# VPAC0_VISS_ECC_AGGR register map
Vendor: Texas Instruments
Peripheral module from a debugger description file (folder J721S2).
Registers are 32-bit, access not given, reset 0x0 unless marked. A register's access mark holds for its fields unless they carry their own. Offsets are as the file gives them; lines under a group give offsets from that group; [hi:lo] are bit positions; {n}, {i} and the like mark numbered series; 'fields as' and 'values as' point back to an identical list; <NAME> marks a mode.

## VPAC0_VISS_ECC_AGGR
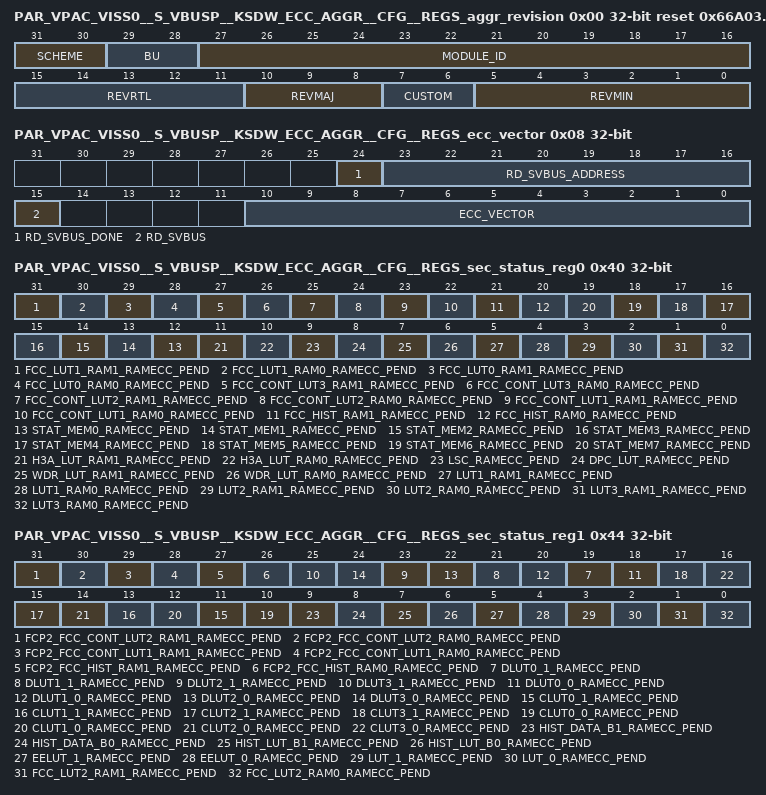
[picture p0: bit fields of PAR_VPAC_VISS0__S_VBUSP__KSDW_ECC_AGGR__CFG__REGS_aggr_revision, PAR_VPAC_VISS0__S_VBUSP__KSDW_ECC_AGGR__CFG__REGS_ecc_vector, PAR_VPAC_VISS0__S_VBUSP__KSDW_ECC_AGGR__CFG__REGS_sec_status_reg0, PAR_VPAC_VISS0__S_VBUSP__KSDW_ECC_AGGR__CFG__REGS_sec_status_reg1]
0x00 PAR_VPAC_VISS0__S_VBUSP__KSDW_ECC_AGGR__CFG__REGS_aggr_revision ro reset 0x66A03A01 — Revision parameters
  [31:30] SCHEME
  [29:28] BU
  [27:16] MODULE_ID
  [15:11] REVRTL — RTL version
  [10:8] REVMAJ — Major version
  [7:6] CUSTOM — Custom version
  [5:0] REVMIN — Minor version
0x08 PAR_VPAC_VISS0__S_VBUSP__KSDW_ECC_AGGR__CFG__REGS_ecc_vector — ECC Vector Register
  [24] RD_SVBUS_DONE — Status to indicate if read on serial VBUS is complete, write of any value will clear this bit. (access R/W1TC)
  [23:16] RD_SVBUS_ADDRESS rw — Read address
  [15] RD_SVBUS — Write 1 to trigger a read on the serial VBUS (access R/W1TS)
  [10:0] ECC_VECTOR rw — Value written to select the corresponding ECC RAM for control or status
0x0C PAR_VPAC_VISS0__S_VBUSP__KSDW_ECC_AGGR__CFG__REGS_misc_status ro reset 0x5D — Misc Status
  [10:0] NUM_RAMS — Indicates the number of RAMS serviced by the ECC aggregator
0x10 PAR_VPAC_VISS0__S_VBUSP__KSDW_ECC_AGGR__CFG__REGS_reserved_svbus rw — Reference other documents that contain the ECC RAM wrapper and EDC controller serial vbus register sets.
  [31:0] DATA — Serial VBUS register data
0x3C PAR_VPAC_VISS0__S_VBUSP__KSDW_ECC_AGGR__CFG__REGS_sec_eoi_reg — EOI Register
  [0] EOI_WR — EOI Register (access R/W1TS)
0x40 PAR_VPAC_VISS0__S_VBUSP__KSDW_ECC_AGGR__CFG__REGS_sec_status_reg0 — Interrupt Status Register 0
  [31] FCC_LUT1_RAM1_RAMECC_PEND — Interrupt Pending Status for fcc_lut1_ram1_ramecc_pend (access R/W1TS)
  [30] FCC_LUT1_RAM0_RAMECC_PEND — Interrupt Pending Status for fcc_lut1_ram0_ramecc_pend (access R/W1TS)
  [29] FCC_LUT0_RAM1_RAMECC_PEND — Interrupt Pending Status for fcc_lut0_ram1_ramecc_pend (access R/W1TS)
  [28] FCC_LUT0_RAM0_RAMECC_PEND — Interrupt Pending Status for fcc_lut0_ram0_ramecc_pend (access R/W1TS)
  [27] FCC_CONT_LUT3_RAM1_RAMECC_PEND — Interrupt Pending Status for fcc_cont_lut3_ram1_ramecc_pend (access R/W1TS)
  [26] FCC_CONT_LUT3_RAM0_RAMECC_PEND — Interrupt Pending Status for fcc_cont_lut3_ram0_ramecc_pend (access R/W1TS)
  [25] FCC_CONT_LUT2_RAM1_RAMECC_PEND — Interrupt Pending Status for fcc_cont_lut2_ram1_ramecc_pend (access R/W1TS)
  [24] FCC_CONT_LUT2_RAM0_RAMECC_PEND — Interrupt Pending Status for fcc_cont_lut2_ram0_ramecc_pend (access R/W1TS)
  [23] FCC_CONT_LUT1_RAM1_RAMECC_PEND — Interrupt Pending Status for fcc_cont_lut1_ram1_ramecc_pend (access R/W1TS)
  [22] FCC_CONT_LUT1_RAM0_RAMECC_PEND — Interrupt Pending Status for fcc_cont_lut1_ram0_ramecc_pend (access R/W1TS)
  [21] FCC_HIST_RAM1_RAMECC_PEND — Interrupt Pending Status for fcc_hist_ram1_ramecc_pend (access R/W1TS)
  [20] FCC_HIST_RAM0_RAMECC_PEND — Interrupt Pending Status for fcc_hist_ram0_ramecc_pend (access R/W1TS)
  [n+12] STAT_MEM{n}_RAMECC_PEND (n=0..7) — Interrupt Pending Status for stat_mem{n}_ramecc_pend (access R/W1TS)
  [11] H3A_LUT_RAM1_RAMECC_PEND — Interrupt Pending Status for h3a_lut_ram1_ramecc_pend (access R/W1TS)
  [10] H3A_LUT_RAM0_RAMECC_PEND — Interrupt Pending Status for h3a_lut_ram0_ramecc_pend (access R/W1TS)
  [9] LSC_RAMECC_PEND — Interrupt Pending Status for lsc_ramecc_pend (access R/W1TS)
  [8] DPC_LUT_RAMECC_PEND — Interrupt Pending Status for dpc_lut_ramecc_pend (access R/W1TS)
  [7] WDR_LUT_RAM1_RAMECC_PEND — Interrupt Pending Status for wdr_lut_ram1_ramecc_pend (access R/W1TS)
  [6] WDR_LUT_RAM0_RAMECC_PEND — Interrupt Pending Status for wdr_lut_ram0_ramecc_pend (access R/W1TS)
  [5] LUT1_RAM1_RAMECC_PEND — Interrupt Pending Status for lut1_ram1_ramecc_pend (access R/W1TS)
  [4] LUT1_RAM0_RAMECC_PEND — Interrupt Pending Status for lut1_ram0_ramecc_pend (access R/W1TS)
  [3] LUT2_RAM1_RAMECC_PEND — Interrupt Pending Status for lut2_ram1_ramecc_pend (access R/W1TS)
  [2] LUT2_RAM0_RAMECC_PEND — Interrupt Pending Status for lut2_ram0_ramecc_pend (access R/W1TS)
  [1] LUT3_RAM1_RAMECC_PEND — Interrupt Pending Status for lut3_ram1_ramecc_pend (access R/W1TS)
  [0] LUT3_RAM0_RAMECC_PEND — Interrupt Pending Status for lut3_ram0_ramecc_pend (access R/W1TS)
0x44 PAR_VPAC_VISS0__S_VBUSP__KSDW_ECC_AGGR__CFG__REGS_sec_status_reg1 — Interrupt Status Register 1
  [31] FCP2_FCC_CONT_LUT2_RAM1_RAMECC_PEND — Interrupt Pending Status for fcp2_fcc_cont_lut2_ram1_ramecc_pend (access R/W1TS)
  [30] FCP2_FCC_CONT_LUT2_RAM0_RAMECC_PEND — Interrupt Pending Status for fcp2_fcc_cont_lut2_ram0_ramecc_pend (access R/W1TS)
  [29] FCP2_FCC_CONT_LUT1_RAM1_RAMECC_PEND — Interrupt Pending Status for fcp2_fcc_cont_lut1_ram1_ramecc_pend (access R/W1TS)
  [28] FCP2_FCC_CONT_LUT1_RAM0_RAMECC_PEND — Interrupt Pending Status for fcp2_fcc_cont_lut1_ram0_ramecc_pend (access R/W1TS)
  [27] FCP2_FCC_HIST_RAM1_RAMECC_PEND — Interrupt Pending Status for fcp2_fcc_hist_ram1_ramecc_pend (access R/W1TS)
  [26] FCP2_FCC_HIST_RAM0_RAMECC_PEND — Interrupt Pending Status for fcp2_fcc_hist_ram0_ramecc_pend (access R/W1TS)
  [2n+19] DLUT{n}_1_RAMECC_PEND (n=0..3) — Interrupt Pending Status for dlut{n}_1_ramecc_pend (access R/W1TS)
  [2n+18] DLUT{n}_0_RAMECC_PEND (n=0..3) — Interrupt Pending Status for dlut{n}_0_ramecc_pend (access R/W1TS)
  [2n+11] CLUT{n}_1_RAMECC_PEND (n=0..3) — Interrupt Pending Status for clut{n}_1_ramecc_pend (access R/W1TS)
  [2n+10] CLUT{n}_0_RAMECC_PEND (n=0..3) — Interrupt Pending Status for clut{n}_0_ramecc_pend (access R/W1TS)
  [9] HIST_DATA_B1_RAMECC_PEND — Interrupt Pending Status for hist_data_b1_ramecc_pend (access R/W1TS)
  [8] HIST_DATA_B0_RAMECC_PEND — Interrupt Pending Status for hist_data_b0_ramecc_pend (access R/W1TS)
  [7] HIST_LUT_B1_RAMECC_PEND — Interrupt Pending Status for hist_lut_b1_ramecc_pend (access R/W1TS)
  [6] HIST_LUT_B0_RAMECC_PEND — Interrupt Pending Status for hist_lut_b0_ramecc_pend (access R/W1TS)
  [5] EELUT_1_RAMECC_PEND — Interrupt Pending Status for eelut_1_ramecc_pend (access R/W1TS)
  [4] EELUT_0_RAMECC_PEND — Interrupt Pending Status for eelut_0_ramecc_pend (access R/W1TS)
  [3] LUT_1_RAMECC_PEND — Interrupt Pending Status for lut_1_ramecc_pend (access R/W1TS)
  [2] LUT_0_RAMECC_PEND — Interrupt Pending Status for lut_0_ramecc_pend (access R/W1TS)
  [1] FCC_LUT2_RAM1_RAMECC_PEND — Interrupt Pending Status for fcc_lut2_ram1_ramecc_pend (access R/W1TS)
  [0] FCC_LUT2_RAM0_RAMECC_PEND — Interrupt Pending Status for fcc_lut2_ram0_ramecc_pend (access R/W1TS)
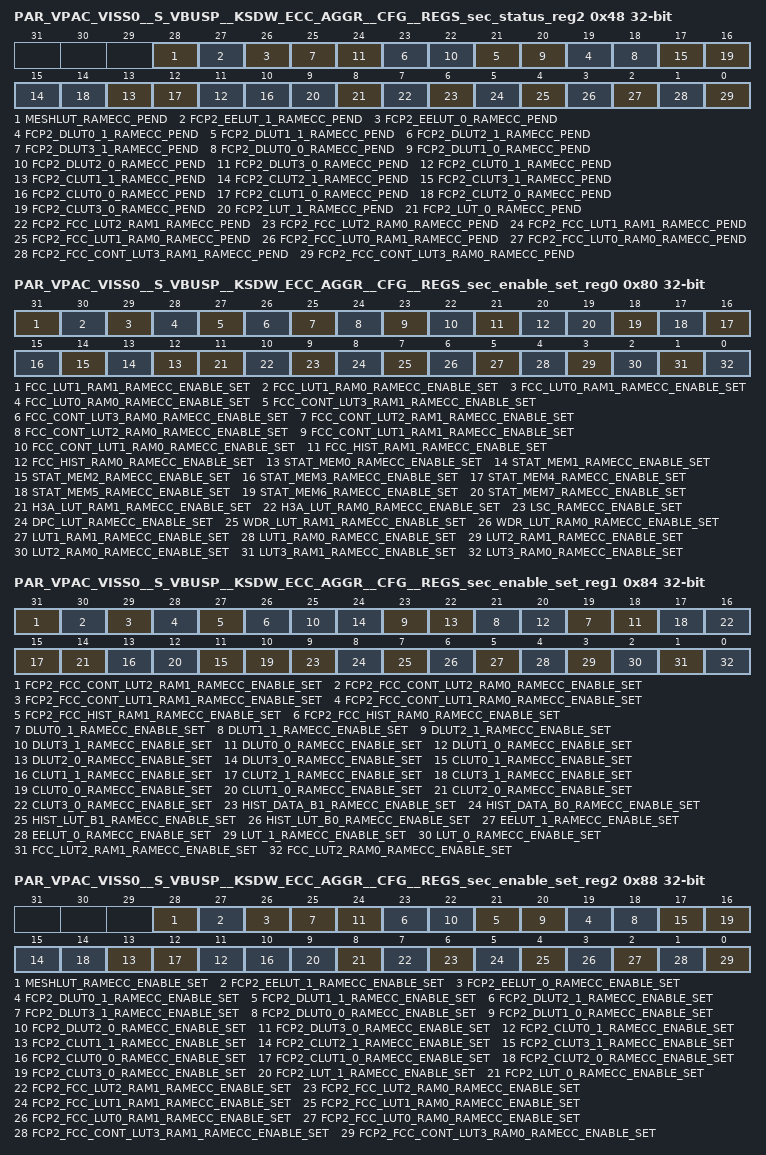
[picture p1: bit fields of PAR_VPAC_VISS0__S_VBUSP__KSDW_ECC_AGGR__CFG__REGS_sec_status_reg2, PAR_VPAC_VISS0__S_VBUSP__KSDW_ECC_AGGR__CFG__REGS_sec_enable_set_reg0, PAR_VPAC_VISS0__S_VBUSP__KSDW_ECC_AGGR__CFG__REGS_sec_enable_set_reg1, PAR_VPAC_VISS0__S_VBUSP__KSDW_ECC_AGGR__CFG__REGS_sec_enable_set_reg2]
0x48 PAR_VPAC_VISS0__S_VBUSP__KSDW_ECC_AGGR__CFG__REGS_sec_status_reg2 — Interrupt Status Register 2
  [28] MESHLUT_RAMECC_PEND — Interrupt Pending Status for meshlut_ramecc_pend (access R/W1TS)
  [27] FCP2_EELUT_1_RAMECC_PEND — Interrupt Pending Status for fcp2_eelut_1_ramecc_pend (access R/W1TS)
  [26] FCP2_EELUT_0_RAMECC_PEND — Interrupt Pending Status for fcp2_eelut_0_ramecc_pend (access R/W1TS)
  [2n+19] FCP2_DLUT{n}_1_RAMECC_PEND (n=0..3) — Interrupt Pending Status for fcp2_dlut{n}_1_ramecc_pend (access R/W1TS)
  [2n+18] FCP2_DLUT{n}_0_RAMECC_PEND (n=0..3) — Interrupt Pending Status for fcp2_dlut{n}_0_ramecc_pend (access R/W1TS)
  [2n+11] FCP2_CLUT{n}_1_RAMECC_PEND (n=0..3) — Interrupt Pending Status for fcp2_clut{n}_1_ramecc_pend (access R/W1TS)
  [2n+10] FCP2_CLUT{n}_0_RAMECC_PEND (n=0..3) — Interrupt Pending Status for fcp2_clut{n}_0_ramecc_pend (access R/W1TS)
  [9] FCP2_LUT_1_RAMECC_PEND — Interrupt Pending Status for fcp2_lut_1_ramecc_pend (access R/W1TS)
  [8] FCP2_LUT_0_RAMECC_PEND — Interrupt Pending Status for fcp2_lut_0_ramecc_pend (access R/W1TS)
  [7] FCP2_FCC_LUT2_RAM1_RAMECC_PEND — Interrupt Pending Status for fcp2_fcc_lut2_ram1_ramecc_pend (access R/W1TS)
  [6] FCP2_FCC_LUT2_RAM0_RAMECC_PEND — Interrupt Pending Status for fcp2_fcc_lut2_ram0_ramecc_pend (access R/W1TS)
  [5] FCP2_FCC_LUT1_RAM1_RAMECC_PEND — Interrupt Pending Status for fcp2_fcc_lut1_ram1_ramecc_pend (access R/W1TS)
  [4] FCP2_FCC_LUT1_RAM0_RAMECC_PEND — Interrupt Pending Status for fcp2_fcc_lut1_ram0_ramecc_pend (access R/W1TS)
  [3] FCP2_FCC_LUT0_RAM1_RAMECC_PEND — Interrupt Pending Status for fcp2_fcc_lut0_ram1_ramecc_pend (access R/W1TS)
  [2] FCP2_FCC_LUT0_RAM0_RAMECC_PEND — Interrupt Pending Status for fcp2_fcc_lut0_ram0_ramecc_pend (access R/W1TS)
  [1] FCP2_FCC_CONT_LUT3_RAM1_RAMECC_PEND — Interrupt Pending Status for fcp2_fcc_cont_lut3_ram1_ramecc_pend (access R/W1TS)
  [0] FCP2_FCC_CONT_LUT3_RAM0_RAMECC_PEND — Interrupt Pending Status for fcp2_fcc_cont_lut3_ram0_ramecc_pend (access R/W1TS)
0x80 PAR_VPAC_VISS0__S_VBUSP__KSDW_ECC_AGGR__CFG__REGS_sec_enable_set_reg0 — Interrupt Enable Set Register 0
  [31] FCC_LUT1_RAM1_RAMECC_ENABLE_SET — Interrupt Enable Set Register for fcc_lut1_ram1_ramecc_pend (access R/W1TS)
  [30] FCC_LUT1_RAM0_RAMECC_ENABLE_SET — Interrupt Enable Set Register for fcc_lut1_ram0_ramecc_pend (access R/W1TS)
  [29] FCC_LUT0_RAM1_RAMECC_ENABLE_SET — Interrupt Enable Set Register for fcc_lut0_ram1_ramecc_pend (access R/W1TS)
  [28] FCC_LUT0_RAM0_RAMECC_ENABLE_SET — Interrupt Enable Set Register for fcc_lut0_ram0_ramecc_pend (access R/W1TS)
  [27] FCC_CONT_LUT3_RAM1_RAMECC_ENABLE_SET — Interrupt Enable Set Register for fcc_cont_lut3_ram1_ramecc_pend (access R/W1TS)
  [26] FCC_CONT_LUT3_RAM0_RAMECC_ENABLE_SET — Interrupt Enable Set Register for fcc_cont_lut3_ram0_ramecc_pend (access R/W1TS)
  [25] FCC_CONT_LUT2_RAM1_RAMECC_ENABLE_SET — Interrupt Enable Set Register for fcc_cont_lut2_ram1_ramecc_pend (access R/W1TS)
  [24] FCC_CONT_LUT2_RAM0_RAMECC_ENABLE_SET — Interrupt Enable Set Register for fcc_cont_lut2_ram0_ramecc_pend (access R/W1TS)
  [23] FCC_CONT_LUT1_RAM1_RAMECC_ENABLE_SET — Interrupt Enable Set Register for fcc_cont_lut1_ram1_ramecc_pend (access R/W1TS)
  [22] FCC_CONT_LUT1_RAM0_RAMECC_ENABLE_SET — Interrupt Enable Set Register for fcc_cont_lut1_ram0_ramecc_pend (access R/W1TS)
  [21] FCC_HIST_RAM1_RAMECC_ENABLE_SET — Interrupt Enable Set Register for fcc_hist_ram1_ramecc_pend (access R/W1TS)
  [20] FCC_HIST_RAM0_RAMECC_ENABLE_SET — Interrupt Enable Set Register for fcc_hist_ram0_ramecc_pend (access R/W1TS)
  [n+12] STAT_MEM{n}_RAMECC_ENABLE_SET (n=0..7) — Interrupt Enable Set Register for stat_mem{n}_ramecc_pend (access R/W1TS)
  [11] H3A_LUT_RAM1_RAMECC_ENABLE_SET — Interrupt Enable Set Register for h3a_lut_ram1_ramecc_pend (access R/W1TS)
  [10] H3A_LUT_RAM0_RAMECC_ENABLE_SET — Interrupt Enable Set Register for h3a_lut_ram0_ramecc_pend (access R/W1TS)
  [9] LSC_RAMECC_ENABLE_SET — Interrupt Enable Set Register for lsc_ramecc_pend (access R/W1TS)
  [8] DPC_LUT_RAMECC_ENABLE_SET — Interrupt Enable Set Register for dpc_lut_ramecc_pend (access R/W1TS)
  [7] WDR_LUT_RAM1_RAMECC_ENABLE_SET — Interrupt Enable Set Register for wdr_lut_ram1_ramecc_pend (access R/W1TS)
  [6] WDR_LUT_RAM0_RAMECC_ENABLE_SET — Interrupt Enable Set Register for wdr_lut_ram0_ramecc_pend (access R/W1TS)
  [5] LUT1_RAM1_RAMECC_ENABLE_SET — Interrupt Enable Set Register for lut1_ram1_ramecc_pend (access R/W1TS)
  [4] LUT1_RAM0_RAMECC_ENABLE_SET — Interrupt Enable Set Register for lut1_ram0_ramecc_pend (access R/W1TS)
  [3] LUT2_RAM1_RAMECC_ENABLE_SET — Interrupt Enable Set Register for lut2_ram1_ramecc_pend (access R/W1TS)
  [2] LUT2_RAM0_RAMECC_ENABLE_SET — Interrupt Enable Set Register for lut2_ram0_ramecc_pend (access R/W1TS)
  [1] LUT3_RAM1_RAMECC_ENABLE_SET — Interrupt Enable Set Register for lut3_ram1_ramecc_pend (access R/W1TS)
  [0] LUT3_RAM0_RAMECC_ENABLE_SET — Interrupt Enable Set Register for lut3_ram0_ramecc_pend (access R/W1TS)
0x84 PAR_VPAC_VISS0__S_VBUSP__KSDW_ECC_AGGR__CFG__REGS_sec_enable_set_reg1 — Interrupt Enable Set Register 1
  [31] FCP2_FCC_CONT_LUT2_RAM1_RAMECC_ENABLE_SET — Interrupt Enable Set Register for fcp2_fcc_cont_lut2_ram1_ramecc_pend (access R/W1TS)
  [30] FCP2_FCC_CONT_LUT2_RAM0_RAMECC_ENABLE_SET — Interrupt Enable Set Register for fcp2_fcc_cont_lut2_ram0_ramecc_pend (access R/W1TS)
  [29] FCP2_FCC_CONT_LUT1_RAM1_RAMECC_ENABLE_SET — Interrupt Enable Set Register for fcp2_fcc_cont_lut1_ram1_ramecc_pend (access R/W1TS)
  [28] FCP2_FCC_CONT_LUT1_RAM0_RAMECC_ENABLE_SET — Interrupt Enable Set Register for fcp2_fcc_cont_lut1_ram0_ramecc_pend (access R/W1TS)
  [27] FCP2_FCC_HIST_RAM1_RAMECC_ENABLE_SET — Interrupt Enable Set Register for fcp2_fcc_hist_ram1_ramecc_pend (access R/W1TS)
  [26] FCP2_FCC_HIST_RAM0_RAMECC_ENABLE_SET — Interrupt Enable Set Register for fcp2_fcc_hist_ram0_ramecc_pend (access R/W1TS)
  [2n+19] DLUT{n}_1_RAMECC_ENABLE_SET (n=0..3) — Interrupt Enable Set Register for dlut{n}_1_ramecc_pend (access R/W1TS)
  [2n+18] DLUT{n}_0_RAMECC_ENABLE_SET (n=0..3) — Interrupt Enable Set Register for dlut{n}_0_ramecc_pend (access R/W1TS)
  [2n+11] CLUT{n}_1_RAMECC_ENABLE_SET (n=0..3) — Interrupt Enable Set Register for clut{n}_1_ramecc_pend (access R/W1TS)
  [2n+10] CLUT{n}_0_RAMECC_ENABLE_SET (n=0..3) — Interrupt Enable Set Register for clut{n}_0_ramecc_pend (access R/W1TS)
  [9] HIST_DATA_B1_RAMECC_ENABLE_SET — Interrupt Enable Set Register for hist_data_b1_ramecc_pend (access R/W1TS)
  [8] HIST_DATA_B0_RAMECC_ENABLE_SET — Interrupt Enable Set Register for hist_data_b0_ramecc_pend (access R/W1TS)
  [7] HIST_LUT_B1_RAMECC_ENABLE_SET — Interrupt Enable Set Register for hist_lut_b1_ramecc_pend (access R/W1TS)
  [6] HIST_LUT_B0_RAMECC_ENABLE_SET — Interrupt Enable Set Register for hist_lut_b0_ramecc_pend (access R/W1TS)
  [5] EELUT_1_RAMECC_ENABLE_SET — Interrupt Enable Set Register for eelut_1_ramecc_pend (access R/W1TS)
  [4] EELUT_0_RAMECC_ENABLE_SET — Interrupt Enable Set Register for eelut_0_ramecc_pend (access R/W1TS)
  [3] LUT_1_RAMECC_ENABLE_SET — Interrupt Enable Set Register for lut_1_ramecc_pend (access R/W1TS)
  [2] LUT_0_RAMECC_ENABLE_SET — Interrupt Enable Set Register for lut_0_ramecc_pend (access R/W1TS)
  [1] FCC_LUT2_RAM1_RAMECC_ENABLE_SET — Interrupt Enable Set Register for fcc_lut2_ram1_ramecc_pend (access R/W1TS)
  [0] FCC_LUT2_RAM0_RAMECC_ENABLE_SET — Interrupt Enable Set Register for fcc_lut2_ram0_ramecc_pend (access R/W1TS)
0x88 PAR_VPAC_VISS0__S_VBUSP__KSDW_ECC_AGGR__CFG__REGS_sec_enable_set_reg2 — Interrupt Enable Set Register 2
  [28] MESHLUT_RAMECC_ENABLE_SET — Interrupt Enable Set Register for meshlut_ramecc_pend (access R/W1TS)
  [27] FCP2_EELUT_1_RAMECC_ENABLE_SET — Interrupt Enable Set Register for fcp2_eelut_1_ramecc_pend (access R/W1TS)
  [26] FCP2_EELUT_0_RAMECC_ENABLE_SET — Interrupt Enable Set Register for fcp2_eelut_0_ramecc_pend (access R/W1TS)
  [2n+19] FCP2_DLUT{n}_1_RAMECC_ENABLE_SET (n=0..3) — Interrupt Enable Set Register for fcp2_dlut{n}_1_ramecc_pend (access R/W1TS)
  [2n+18] FCP2_DLUT{n}_0_RAMECC_ENABLE_SET (n=0..3) — Interrupt Enable Set Register for fcp2_dlut{n}_0_ramecc_pend (access R/W1TS)
  [2n+11] FCP2_CLUT{n}_1_RAMECC_ENABLE_SET (n=0..3) — Interrupt Enable Set Register for fcp2_clut{n}_1_ramecc_pend (access R/W1TS)
  [2n+10] FCP2_CLUT{n}_0_RAMECC_ENABLE_SET (n=0..3) — Interrupt Enable Set Register for fcp2_clut{n}_0_ramecc_pend (access R/W1TS)
  [9] FCP2_LUT_1_RAMECC_ENABLE_SET — Interrupt Enable Set Register for fcp2_lut_1_ramecc_pend (access R/W1TS)
  [8] FCP2_LUT_0_RAMECC_ENABLE_SET — Interrupt Enable Set Register for fcp2_lut_0_ramecc_pend (access R/W1TS)
  [7] FCP2_FCC_LUT2_RAM1_RAMECC_ENABLE_SET — Interrupt Enable Set Register for fcp2_fcc_lut2_ram1_ramecc_pend (access R/W1TS)
  [6] FCP2_FCC_LUT2_RAM0_RAMECC_ENABLE_SET — Interrupt Enable Set Register for fcp2_fcc_lut2_ram0_ramecc_pend (access R/W1TS)
  [5] FCP2_FCC_LUT1_RAM1_RAMECC_ENABLE_SET — Interrupt Enable Set Register for fcp2_fcc_lut1_ram1_ramecc_pend (access R/W1TS)
  [4] FCP2_FCC_LUT1_RAM0_RAMECC_ENABLE_SET — Interrupt Enable Set Register for fcp2_fcc_lut1_ram0_ramecc_pend (access R/W1TS)
  [3] FCP2_FCC_LUT0_RAM1_RAMECC_ENABLE_SET — Interrupt Enable Set Register for fcp2_fcc_lut0_ram1_ramecc_pend (access R/W1TS)
  [2] FCP2_FCC_LUT0_RAM0_RAMECC_ENABLE_SET — Interrupt Enable Set Register for fcp2_fcc_lut0_ram0_ramecc_pend (access R/W1TS)
  [1] FCP2_FCC_CONT_LUT3_RAM1_RAMECC_ENABLE_SET — Interrupt Enable Set Register for fcp2_fcc_cont_lut3_ram1_ramecc_pend (access R/W1TS)
  [0] FCP2_FCC_CONT_LUT3_RAM0_RAMECC_ENABLE_SET — Interrupt Enable Set Register for fcp2_fcc_cont_lut3_ram0_ramecc_pend (access R/W1TS)
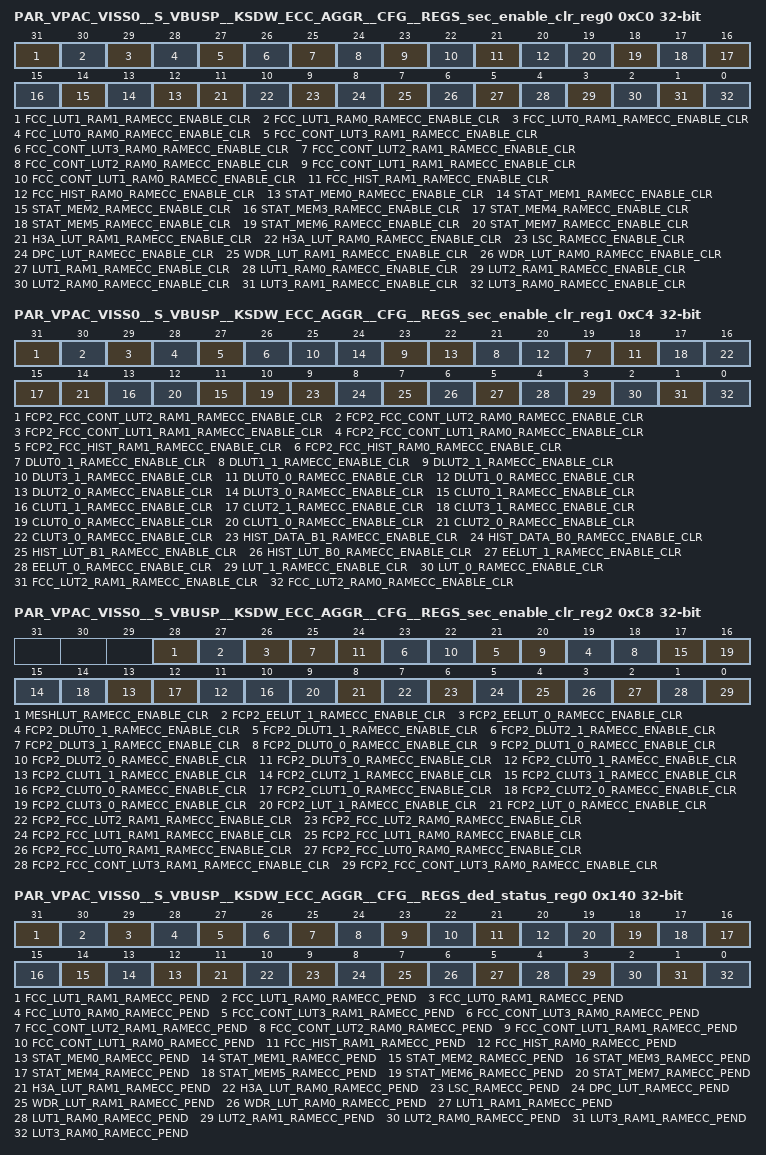
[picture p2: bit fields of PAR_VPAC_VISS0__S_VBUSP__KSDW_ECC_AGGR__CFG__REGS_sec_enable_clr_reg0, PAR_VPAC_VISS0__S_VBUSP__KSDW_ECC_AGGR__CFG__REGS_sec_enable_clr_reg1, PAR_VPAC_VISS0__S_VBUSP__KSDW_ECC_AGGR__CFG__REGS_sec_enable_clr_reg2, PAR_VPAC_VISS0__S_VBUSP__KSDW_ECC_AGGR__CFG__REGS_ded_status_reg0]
0xC0 PAR_VPAC_VISS0__S_VBUSP__KSDW_ECC_AGGR__CFG__REGS_sec_enable_clr_reg0 — Interrupt Enable Clear Register 0
  [31] FCC_LUT1_RAM1_RAMECC_ENABLE_CLR — Interrupt Enable Clear Register for fcc_lut1_ram1_ramecc_pend (access R/W1TC)
  [30] FCC_LUT1_RAM0_RAMECC_ENABLE_CLR — Interrupt Enable Clear Register for fcc_lut1_ram0_ramecc_pend (access R/W1TC)
  [29] FCC_LUT0_RAM1_RAMECC_ENABLE_CLR — Interrupt Enable Clear Register for fcc_lut0_ram1_ramecc_pend (access R/W1TC)
  [28] FCC_LUT0_RAM0_RAMECC_ENABLE_CLR — Interrupt Enable Clear Register for fcc_lut0_ram0_ramecc_pend (access R/W1TC)
  [27] FCC_CONT_LUT3_RAM1_RAMECC_ENABLE_CLR — Interrupt Enable Clear Register for fcc_cont_lut3_ram1_ramecc_pend (access R/W1TC)
  [26] FCC_CONT_LUT3_RAM0_RAMECC_ENABLE_CLR — Interrupt Enable Clear Register for fcc_cont_lut3_ram0_ramecc_pend (access R/W1TC)
  [25] FCC_CONT_LUT2_RAM1_RAMECC_ENABLE_CLR — Interrupt Enable Clear Register for fcc_cont_lut2_ram1_ramecc_pend (access R/W1TC)
  [24] FCC_CONT_LUT2_RAM0_RAMECC_ENABLE_CLR — Interrupt Enable Clear Register for fcc_cont_lut2_ram0_ramecc_pend (access R/W1TC)
  [23] FCC_CONT_LUT1_RAM1_RAMECC_ENABLE_CLR — Interrupt Enable Clear Register for fcc_cont_lut1_ram1_ramecc_pend (access R/W1TC)
  [22] FCC_CONT_LUT1_RAM0_RAMECC_ENABLE_CLR — Interrupt Enable Clear Register for fcc_cont_lut1_ram0_ramecc_pend (access R/W1TC)
  [21] FCC_HIST_RAM1_RAMECC_ENABLE_CLR — Interrupt Enable Clear Register for fcc_hist_ram1_ramecc_pend (access R/W1TC)
  [20] FCC_HIST_RAM0_RAMECC_ENABLE_CLR — Interrupt Enable Clear Register for fcc_hist_ram0_ramecc_pend (access R/W1TC)
  [n+12] STAT_MEM{n}_RAMECC_ENABLE_CLR (n=0..7) — Interrupt Enable Clear Register for stat_mem{n}_ramecc_pend (access R/W1TC)
  [11] H3A_LUT_RAM1_RAMECC_ENABLE_CLR — Interrupt Enable Clear Register for h3a_lut_ram1_ramecc_pend (access R/W1TC)
  [10] H3A_LUT_RAM0_RAMECC_ENABLE_CLR — Interrupt Enable Clear Register for h3a_lut_ram0_ramecc_pend (access R/W1TC)
  [9] LSC_RAMECC_ENABLE_CLR — Interrupt Enable Clear Register for lsc_ramecc_pend (access R/W1TC)
  [8] DPC_LUT_RAMECC_ENABLE_CLR — Interrupt Enable Clear Register for dpc_lut_ramecc_pend (access R/W1TC)
  [7] WDR_LUT_RAM1_RAMECC_ENABLE_CLR — Interrupt Enable Clear Register for wdr_lut_ram1_ramecc_pend (access R/W1TC)
  [6] WDR_LUT_RAM0_RAMECC_ENABLE_CLR — Interrupt Enable Clear Register for wdr_lut_ram0_ramecc_pend (access R/W1TC)
  [5] LUT1_RAM1_RAMECC_ENABLE_CLR — Interrupt Enable Clear Register for lut1_ram1_ramecc_pend (access R/W1TC)
  [4] LUT1_RAM0_RAMECC_ENABLE_CLR — Interrupt Enable Clear Register for lut1_ram0_ramecc_pend (access R/W1TC)
  [3] LUT2_RAM1_RAMECC_ENABLE_CLR — Interrupt Enable Clear Register for lut2_ram1_ramecc_pend (access R/W1TC)
  [2] LUT2_RAM0_RAMECC_ENABLE_CLR — Interrupt Enable Clear Register for lut2_ram0_ramecc_pend (access R/W1TC)
  [1] LUT3_RAM1_RAMECC_ENABLE_CLR — Interrupt Enable Clear Register for lut3_ram1_ramecc_pend (access R/W1TC)
  [0] LUT3_RAM0_RAMECC_ENABLE_CLR — Interrupt Enable Clear Register for lut3_ram0_ramecc_pend (access R/W1TC)
0xC4 PAR_VPAC_VISS0__S_VBUSP__KSDW_ECC_AGGR__CFG__REGS_sec_enable_clr_reg1 — Interrupt Enable Clear Register 1
  [31] FCP2_FCC_CONT_LUT2_RAM1_RAMECC_ENABLE_CLR — Interrupt Enable Clear Register for fcp2_fcc_cont_lut2_ram1_ramecc_pend (access R/W1TC)
  [30] FCP2_FCC_CONT_LUT2_RAM0_RAMECC_ENABLE_CLR — Interrupt Enable Clear Register for fcp2_fcc_cont_lut2_ram0_ramecc_pend (access R/W1TC)
  [29] FCP2_FCC_CONT_LUT1_RAM1_RAMECC_ENABLE_CLR — Interrupt Enable Clear Register for fcp2_fcc_cont_lut1_ram1_ramecc_pend (access R/W1TC)
  [28] FCP2_FCC_CONT_LUT1_RAM0_RAMECC_ENABLE_CLR — Interrupt Enable Clear Register for fcp2_fcc_cont_lut1_ram0_ramecc_pend (access R/W1TC)
  [27] FCP2_FCC_HIST_RAM1_RAMECC_ENABLE_CLR — Interrupt Enable Clear Register for fcp2_fcc_hist_ram1_ramecc_pend (access R/W1TC)
  [26] FCP2_FCC_HIST_RAM0_RAMECC_ENABLE_CLR — Interrupt Enable Clear Register for fcp2_fcc_hist_ram0_ramecc_pend (access R/W1TC)
  [2n+19] DLUT{n}_1_RAMECC_ENABLE_CLR (n=0..3) — Interrupt Enable Clear Register for dlut{n}_1_ramecc_pend (access R/W1TC)
  [2n+18] DLUT{n}_0_RAMECC_ENABLE_CLR (n=0..3) — Interrupt Enable Clear Register for dlut{n}_0_ramecc_pend (access R/W1TC)
  [2n+11] CLUT{n}_1_RAMECC_ENABLE_CLR (n=0..3) — Interrupt Enable Clear Register for clut{n}_1_ramecc_pend (access R/W1TC)
  [2n+10] CLUT{n}_0_RAMECC_ENABLE_CLR (n=0..3) — Interrupt Enable Clear Register for clut{n}_0_ramecc_pend (access R/W1TC)
  [9] HIST_DATA_B1_RAMECC_ENABLE_CLR — Interrupt Enable Clear Register for hist_data_b1_ramecc_pend (access R/W1TC)
  [8] HIST_DATA_B0_RAMECC_ENABLE_CLR — Interrupt Enable Clear Register for hist_data_b0_ramecc_pend (access R/W1TC)
  [7] HIST_LUT_B1_RAMECC_ENABLE_CLR — Interrupt Enable Clear Register for hist_lut_b1_ramecc_pend (access R/W1TC)
  [6] HIST_LUT_B0_RAMECC_ENABLE_CLR — Interrupt Enable Clear Register for hist_lut_b0_ramecc_pend (access R/W1TC)
  [5] EELUT_1_RAMECC_ENABLE_CLR — Interrupt Enable Clear Register for eelut_1_ramecc_pend (access R/W1TC)
  [4] EELUT_0_RAMECC_ENABLE_CLR — Interrupt Enable Clear Register for eelut_0_ramecc_pend (access R/W1TC)
  [3] LUT_1_RAMECC_ENABLE_CLR — Interrupt Enable Clear Register for lut_1_ramecc_pend (access R/W1TC)
  [2] LUT_0_RAMECC_ENABLE_CLR — Interrupt Enable Clear Register for lut_0_ramecc_pend (access R/W1TC)
  [1] FCC_LUT2_RAM1_RAMECC_ENABLE_CLR — Interrupt Enable Clear Register for fcc_lut2_ram1_ramecc_pend (access R/W1TC)
  [0] FCC_LUT2_RAM0_RAMECC_ENABLE_CLR — Interrupt Enable Clear Register for fcc_lut2_ram0_ramecc_pend (access R/W1TC)
0xC8 PAR_VPAC_VISS0__S_VBUSP__KSDW_ECC_AGGR__CFG__REGS_sec_enable_clr_reg2 — Interrupt Enable Clear Register 2
  [28] MESHLUT_RAMECC_ENABLE_CLR — Interrupt Enable Clear Register for meshlut_ramecc_pend (access R/W1TC)
  [27] FCP2_EELUT_1_RAMECC_ENABLE_CLR — Interrupt Enable Clear Register for fcp2_eelut_1_ramecc_pend (access R/W1TC)
  [26] FCP2_EELUT_0_RAMECC_ENABLE_CLR — Interrupt Enable Clear Register for fcp2_eelut_0_ramecc_pend (access R/W1TC)
  [2n+19] FCP2_DLUT{n}_1_RAMECC_ENABLE_CLR (n=0..3) — Interrupt Enable Clear Register for fcp2_dlut{n}_1_ramecc_pend (access R/W1TC)
  [2n+18] FCP2_DLUT{n}_0_RAMECC_ENABLE_CLR (n=0..3) — Interrupt Enable Clear Register for fcp2_dlut{n}_0_ramecc_pend (access R/W1TC)
  [2n+11] FCP2_CLUT{n}_1_RAMECC_ENABLE_CLR (n=0..3) — Interrupt Enable Clear Register for fcp2_clut{n}_1_ramecc_pend (access R/W1TC)
  [2n+10] FCP2_CLUT{n}_0_RAMECC_ENABLE_CLR (n=0..3) — Interrupt Enable Clear Register for fcp2_clut{n}_0_ramecc_pend (access R/W1TC)
  [9] FCP2_LUT_1_RAMECC_ENABLE_CLR — Interrupt Enable Clear Register for fcp2_lut_1_ramecc_pend (access R/W1TC)
  [8] FCP2_LUT_0_RAMECC_ENABLE_CLR — Interrupt Enable Clear Register for fcp2_lut_0_ramecc_pend (access R/W1TC)
  [7] FCP2_FCC_LUT2_RAM1_RAMECC_ENABLE_CLR — Interrupt Enable Clear Register for fcp2_fcc_lut2_ram1_ramecc_pend (access R/W1TC)
  [6] FCP2_FCC_LUT2_RAM0_RAMECC_ENABLE_CLR — Interrupt Enable Clear Register for fcp2_fcc_lut2_ram0_ramecc_pend (access R/W1TC)
  [5] FCP2_FCC_LUT1_RAM1_RAMECC_ENABLE_CLR — Interrupt Enable Clear Register for fcp2_fcc_lut1_ram1_ramecc_pend (access R/W1TC)
  [4] FCP2_FCC_LUT1_RAM0_RAMECC_ENABLE_CLR — Interrupt Enable Clear Register for fcp2_fcc_lut1_ram0_ramecc_pend (access R/W1TC)
  [3] FCP2_FCC_LUT0_RAM1_RAMECC_ENABLE_CLR — Interrupt Enable Clear Register for fcp2_fcc_lut0_ram1_ramecc_pend (access R/W1TC)
  [2] FCP2_FCC_LUT0_RAM0_RAMECC_ENABLE_CLR — Interrupt Enable Clear Register for fcp2_fcc_lut0_ram0_ramecc_pend (access R/W1TC)
  [1] FCP2_FCC_CONT_LUT3_RAM1_RAMECC_ENABLE_CLR — Interrupt Enable Clear Register for fcp2_fcc_cont_lut3_ram1_ramecc_pend (access R/W1TC)
  [0] FCP2_FCC_CONT_LUT3_RAM0_RAMECC_ENABLE_CLR — Interrupt Enable Clear Register for fcp2_fcc_cont_lut3_ram0_ramecc_pend (access R/W1TC)
0x13C PAR_VPAC_VISS0__S_VBUSP__KSDW_ECC_AGGR__CFG__REGS_ded_eoi_reg — EOI Register
  [0] EOI_WR — EOI Register (access R/W1TS)
0x140 PAR_VPAC_VISS0__S_VBUSP__KSDW_ECC_AGGR__CFG__REGS_ded_status_reg0 — Interrupt Status Register 0
  fields as PAR_VPAC_VISS0__S_VBUSP__KSDW_ECC_AGGR__CFG__REGS_sec_status_reg0
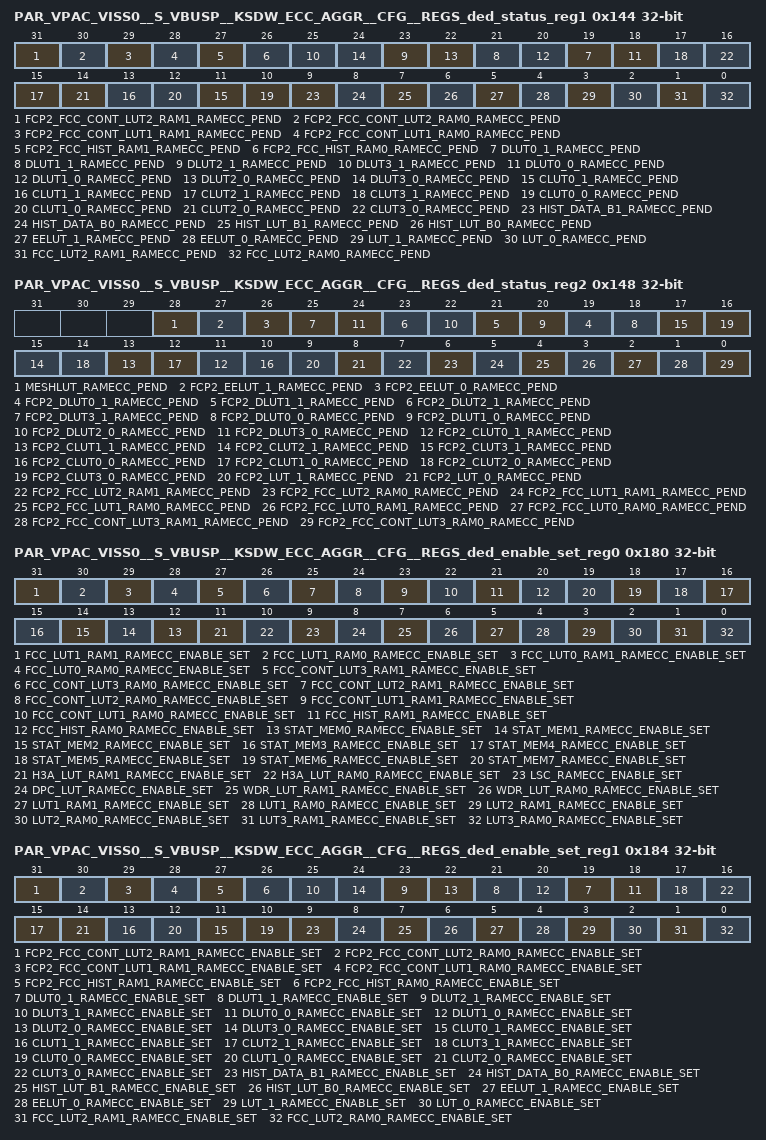
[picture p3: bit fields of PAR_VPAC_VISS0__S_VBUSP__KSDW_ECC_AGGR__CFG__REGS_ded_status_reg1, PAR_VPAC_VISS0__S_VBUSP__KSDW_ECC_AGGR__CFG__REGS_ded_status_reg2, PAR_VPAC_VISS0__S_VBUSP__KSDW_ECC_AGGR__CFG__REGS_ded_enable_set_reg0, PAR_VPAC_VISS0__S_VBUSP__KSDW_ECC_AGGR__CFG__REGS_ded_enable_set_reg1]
0x144 PAR_VPAC_VISS0__S_VBUSP__KSDW_ECC_AGGR__CFG__REGS_ded_status_reg1 — Interrupt Status Register 1
  fields as PAR_VPAC_VISS0__S_VBUSP__KSDW_ECC_AGGR__CFG__REGS_sec_status_reg1
0x148 PAR_VPAC_VISS0__S_VBUSP__KSDW_ECC_AGGR__CFG__REGS_ded_status_reg2 — Interrupt Status Register 2
  fields as PAR_VPAC_VISS0__S_VBUSP__KSDW_ECC_AGGR__CFG__REGS_sec_status_reg2
0x180 PAR_VPAC_VISS0__S_VBUSP__KSDW_ECC_AGGR__CFG__REGS_ded_enable_set_reg0 — Interrupt Enable Set Register 0
  fields as PAR_VPAC_VISS0__S_VBUSP__KSDW_ECC_AGGR__CFG__REGS_sec_enable_set_reg0
0x184 PAR_VPAC_VISS0__S_VBUSP__KSDW_ECC_AGGR__CFG__REGS_ded_enable_set_reg1 — Interrupt Enable Set Register 1
  fields as PAR_VPAC_VISS0__S_VBUSP__KSDW_ECC_AGGR__CFG__REGS_sec_enable_set_reg1
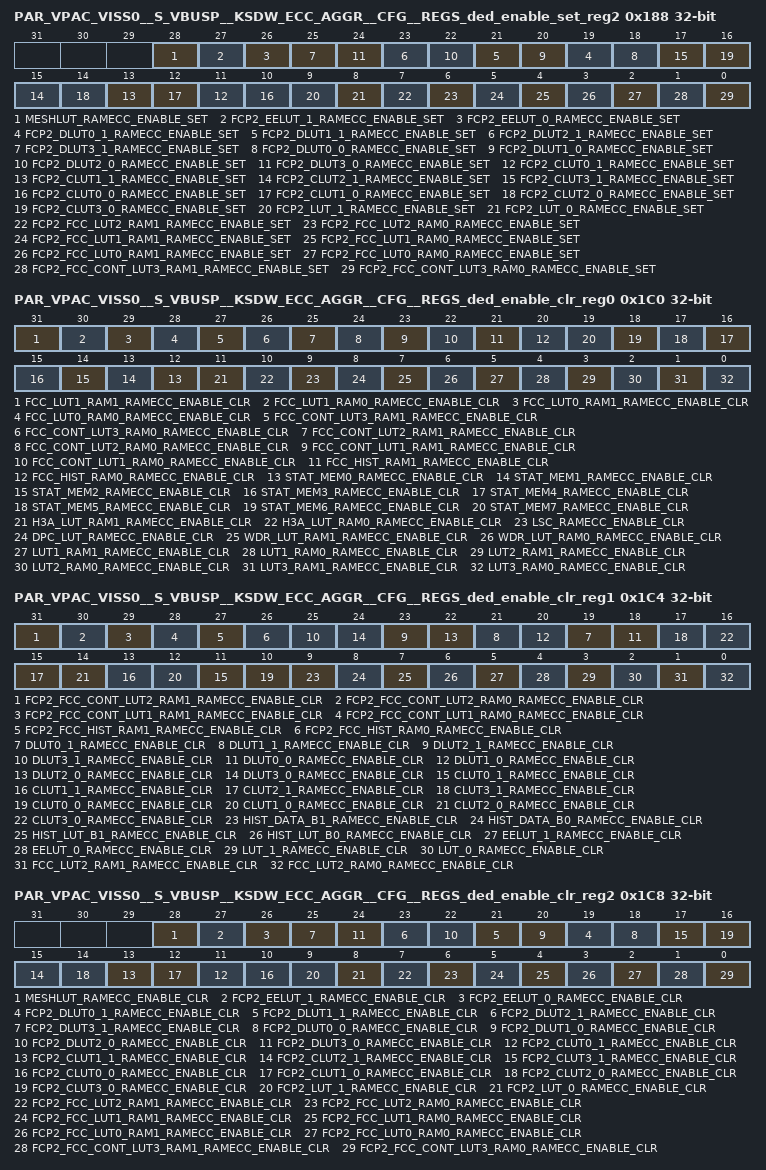
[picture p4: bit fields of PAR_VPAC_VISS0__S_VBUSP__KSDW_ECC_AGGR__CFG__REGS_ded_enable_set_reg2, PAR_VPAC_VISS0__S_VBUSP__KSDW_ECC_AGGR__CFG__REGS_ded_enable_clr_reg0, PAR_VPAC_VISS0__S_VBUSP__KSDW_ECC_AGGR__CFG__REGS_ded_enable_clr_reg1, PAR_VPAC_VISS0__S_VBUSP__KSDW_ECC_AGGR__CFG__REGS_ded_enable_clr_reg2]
0x188 PAR_VPAC_VISS0__S_VBUSP__KSDW_ECC_AGGR__CFG__REGS_ded_enable_set_reg2 — Interrupt Enable Set Register 2
  fields as PAR_VPAC_VISS0__S_VBUSP__KSDW_ECC_AGGR__CFG__REGS_sec_enable_set_reg2
0x1C0 PAR_VPAC_VISS0__S_VBUSP__KSDW_ECC_AGGR__CFG__REGS_ded_enable_clr_reg0 — Interrupt Enable Clear Register 0
  fields as PAR_VPAC_VISS0__S_VBUSP__KSDW_ECC_AGGR__CFG__REGS_sec_enable_clr_reg0
0x1C4 PAR_VPAC_VISS0__S_VBUSP__KSDW_ECC_AGGR__CFG__REGS_ded_enable_clr_reg1 — Interrupt Enable Clear Register 1
  fields as PAR_VPAC_VISS0__S_VBUSP__KSDW_ECC_AGGR__CFG__REGS_sec_enable_clr_reg1
0x1C8 PAR_VPAC_VISS0__S_VBUSP__KSDW_ECC_AGGR__CFG__REGS_ded_enable_clr_reg2 — Interrupt Enable Clear Register 2
  fields as PAR_VPAC_VISS0__S_VBUSP__KSDW_ECC_AGGR__CFG__REGS_sec_enable_clr_reg2
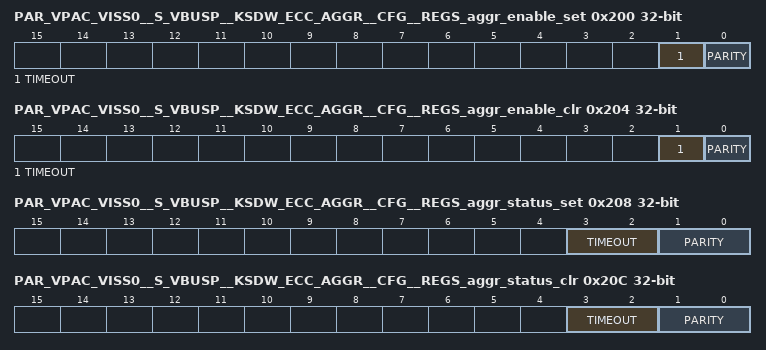
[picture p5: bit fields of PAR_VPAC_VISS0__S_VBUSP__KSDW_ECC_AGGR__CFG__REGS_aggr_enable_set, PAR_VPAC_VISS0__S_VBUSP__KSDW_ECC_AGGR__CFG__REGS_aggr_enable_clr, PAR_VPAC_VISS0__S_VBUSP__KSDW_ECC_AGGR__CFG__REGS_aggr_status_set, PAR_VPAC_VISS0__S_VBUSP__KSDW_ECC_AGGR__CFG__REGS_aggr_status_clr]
0x200 PAR_VPAC_VISS0__S_VBUSP__KSDW_ECC_AGGR__CFG__REGS_aggr_enable_set — AGGR interrupt enable set Register
  [1] TIMEOUT — interrupt enable set for svbus timeout errors (access R/W1TS)
  [0] PARITY — interrupt enable set for parity errors (access R/W1TS)
0x204 PAR_VPAC_VISS0__S_VBUSP__KSDW_ECC_AGGR__CFG__REGS_aggr_enable_clr — AGGR interrupt enable clear Register
  [1] TIMEOUT — interrupt enable clear for svbus timeout errors (access R/W1TC)
  [0] PARITY — interrupt enable clear for parity errors (access R/W1TC)
0x208 PAR_VPAC_VISS0__S_VBUSP__KSDW_ECC_AGGR__CFG__REGS_aggr_status_set — AGGR interrupt status set Register
  [3:2] TIMEOUT — interrupt status set for svbus timeout errors (access R/WI)
  [1:0] PARITY — interrupt status set for parity errors (access R/WI)
0x20C PAR_VPAC_VISS0__S_VBUSP__KSDW_ECC_AGGR__CFG__REGS_aggr_status_clr — AGGR interrupt status clear Register
  [3:2] TIMEOUT — interrupt status clear for svbus timeout errors (access R/WD)
  [1:0] PARITY — interrupt status clear for parity errors (access R/WD)
